# LPC865 register map
Vendor: nxp.com; File version: 1.0
CPU: CM0PLUS r0p0, little endian, no MPU, no FPU, VTOR, 2 interrupt priority bits
Registers are 32-bit, read-write, reset 0x0 unless marked. A register's access mark holds for its fields unless they carry their own. Offsets are from the block's base; [hi:lo] are bit positions; {n}, {i} and the like mark numbered series.

## PMU — LPC86x PMU
Base 0x40020000
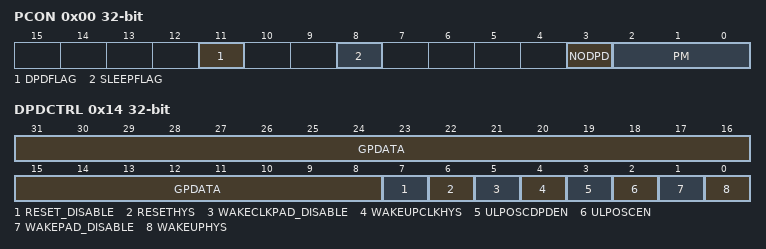
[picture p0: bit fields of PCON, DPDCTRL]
0x00 PCON — Power control register
  [11] DPDFLAG — Deep power-down flag
    0=NOT_DEEP_POWER_DOWN (Not Deep power-down. Read: Deep power-down mode not entered. Write: No effect.); 1=DEEP_POWER_DOWN (Deep power-down. Read: Deep power-down mode entered. Write: Clear the Deep power-down flag.)
  [8] SLEEPFLAG — Sleep mode flag
    0=ACTIVE_MODE (Active mode. Read: No power-down mode entered. Part is in Active mode. Write: No effect.); 1=LOW_POWER_MODE (Low power mode. Read: Sleep, Deep-sleep or Power-down mode entered. Write: Writing a 1 clears the SLEEPFLAG bit to 0.)
  [3] NODPD — A 1 in this bit prevents entry to Deep power-down mode when 0x3 is written to the PM field above, the SLEEPDEEP bit is set, and a WFI is executed. This bit is cleared only by power-on reset, so writing a one to this bit locks the part in a mode in which Deep power-down mode is blocked.
  [2:0] PM — Power mode
    0=DEFAULT (Default. The part is in active or sleep mode.); 1=DEEP_SLEEP_MODE (Deep-sleep mode. ARM WFI will enter Deep-sleep mode.); 2=POWER_DOWN_MODE (Power-down mode. ARM WFI will enter Power-down mode.); 3=DEEP_POWER_DOWN_MODE (Deep power-down mode. ARM WFI will enter Deep-power down mode (ARM Cortex-M0+ core powered-down).)
{0x4+4i} GPREG[{i}] (i=0..3) — General purpose register N
  [31:0] GPDATA — Data retained during Deep power-down mode.
0x14 DPDCTRL — Deep power-down control register. Also includes bits for general purpose storage.
  [31:8] GPDATA — Data retained during Deep power-down mode.
  [7] RESET_DISABLE — RESET pin disable. Setting this bit disables the reset wake-up function, so the pin can be used for other purposes. Remark: Setting this bit is not necessary if deep power-down mode is not used.
    0=ENABLED (Enabled. The reset wake-up function is enabled on pin PIO0_5.); 1=DISABLED (Disabled. Setting this bit disables the wake-up function on pin PIO0_5.)
  [6] RESETHYS — RESET pin hysteresis enable.
    0=DISABLED (Disabled. Hysteresis for RESET pin disabled.); 1=ENABLED (Enabled. Hysteresis for RESET pin enabled.)
  [5] WAKECLKPAD_DISABLE — Disable the external clock input for the self-wake-up timer. Setting this bit enables the self-wake-up timer clock pin WKTCLKLIN. To minimize power consumption, especially in deep power-down mode, disable this clock input when not using the external clock option for the self-wake-up timer.
    0=DISABLED (Disabled. Setting this bit disables external clock input on pin PIO0_28.); 1=ENABLED (Enabled. The external clock input for the self wake-up timer is enabled on pin PIO0_28.)
  [4] WAKEUPCLKHYS — External clock input for the self wake-up timer WKTCLKIN hysteresis enable.
    0=DISABLED (Disabled. Hysteresis for WAKEUP clock pin disabled.); 1=ENABLED (Enabled. Hysteresis for WAKEUP clock pin enabled.)
  [3] ULPOSCDPDEN — causes the low-power oscillator to remain running during Deep power-down mode provided that bit 2 in this register is set as well. You must set this bit for the self wake-up timer to be able to wake up the part from Deep power-down mode. Remark: Do not set this bit unless you use the self wake-up timer with the low-power oscillator clock source to wake up from Deep power-down mode.
    0=DISABLED; 1=ENABLED
  [2] ULPOSCEN — Enable the low-power oscillator for use with the 10 kHz self wake-up timer clock. You must set this bit if the CLKSEL bit in the self wake-up timer CTRL bit is set. Do not enable the low-power oscillator if the self wake-up timer is clocked by the divided IRC or the external clock input.
    0=DISABLED; 1=ENABLED
  [1] WAKEPAD_DISABLE — WAKEUP pin disable. Setting this bit disables the wake-up pin, so it can be used for other purposes. Remark: Never set this bit if you intend to use a pin to wake up the part from Deep power-down mode. You can only disable the wake-up pin if the self wake-up timer is enabled and configured. Remark: Setting this bit is not necessary if Deep power-down mode is not used.
    0=ENABLED (Enabled. The wake-up function is enabled on pin PIO0_4.); 1=DISABLED (Disabled. Setting this bit disables the wake-up function on pin PIO0_4.)
  [0] WAKEUPHYS — WAKEUP pin hysteresis enable
    0=DISABLED (Disabled. Hysteresis for WAKEUP pin disabled.); 1=ENABLED (Enabled. Hysteresis for WAKEUP pin enabled.)
